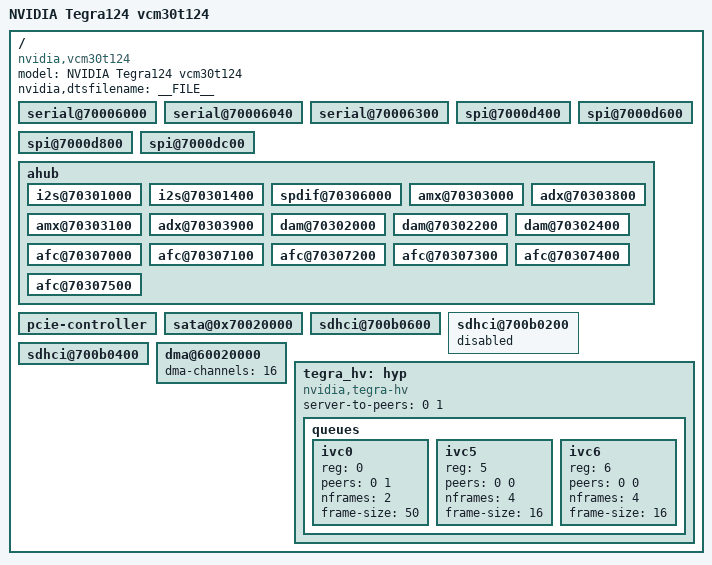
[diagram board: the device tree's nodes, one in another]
/*
 * arch/arm/boot/dts/tegra124-vcm30_t124.dts
 *
 * Copyright (c) 2013-2014, NVIDIA CORPORATION.  All rights reserved.
 *
 * This program is free software; you can redistribute it and/or modify
 * it under the terms of the GNU General Public License as published by
 * the Free Software Foundation; version 2 of the License.
 *
 * This program is distributed in the hope that it will be useful, but WITHOUT
 * ANY WARRANTY; without even the implied warranty of MERCHANTABILITY or
 * FITNESS FOR A PARTICULAR PURPOSE.  See the GNU General Public License for
 * more details.
 *
 * You should have received a copy of the GNU General Public License along
 * with this program; if not, write to the Free Software Foundation, Inc.,
 * 51 Franklin Street, Fifth Floor, Boston, MA  02110-1301, USA.
 *
 */

 /dts-v1/;

#include "tegra124-vcm30_t124.dtsi"
#include <tegra124-platforms/tegra124-vcm30-t124-gpio-default.dtsi>
#include <tegra124-platforms/tegra124-vcm30-t124-pinmux.dtsi>


/ {
	model = "NVIDIA Tegra124 vcm30t124";
	compatible = "nvidia,vcm30t124", "nvidia,tegra124";
	nvidia,dtsfilename = __FILE__;
	#address-cells = <2>;
	#size-cells = <2>;

        serial@70006000 {
                status = "okay";
        };

        serial@70006040 {
                status = "okay";
        };

        serial@70006300 {
                status = "okay";
        };

	spi@7000d400 {
		status = "okay";
	};

	spi@7000d600 {
		status = "okay";
	};

	spi@7000d800 {
		status = "okay";
	};

	spi@7000dc00 {
		status = "okay";
	};

	ahub {
		status = "okay";

		i2s@70301000 {
			status = "okay";
		};
		i2s@70301400 {
			status = "okay";
		};
		spdif@70306000 {
			status = "okay";
		};
		amx@70303000 {
			status = "okay";
		};
		adx@70303800 {
			status = "okay";
		};
		amx@70303100 {
			status = "okay";
		};
		adx@70303900 {
			status = "okay";
		};
		dam@70302000 {
			status = "okay";
		};
		dam@70302200 {
			status = "okay";
		};
		dam@70302400 {
			status = "okay";
		};
		afc@70307000 {
			status = "okay";
		};
		afc@70307100 {
			status = "okay";
		};
		afc@70307200 {
			status = "okay";
		};
		afc@70307300 {
			status = "okay";
		};
		afc@70307400 {
			status = "okay";
		};
		afc@70307500 {
			status = "okay";
		};
	};

	pcie-controller {
		status = "okay";
	};

	sata@0x70020000 {
		status = "okay";
	};

	sdhci@700b0600 {
		status = "okay";
	};

	sdhci@700b0200 {
		status = "disabled";
	};

	sdhci@700b0400 {
		status = "okay";
	};

	dma@60020000 {
		dma-channels = <16>;
		status = "okay";
	};

	tegra_hv: hyp {
		compatible = "nvidia,tegra-hv";
		status = "okay";

		server-to-peers = <0 1>;

		queues {
			#address-cells = <1>;
			#size-cells = <0>;

			/* guest 0 <-> guest 1 (frame based) */
			ivc0 {
				reg = <0>;
				peers = <0 1>;
				nframes = <2>;
				frame-size = <50>;
			};

			/* placeholder for serial & net IVC channels */

			/* guest 0 <-> guest 0 (loop) */
			ivc5 {
				reg = <5>;
				peers = <0 0>;
				nframes = <4>;
				frame-size = <16>;
			};

			/* guest 0 <-> guest 0 (loop) */
			ivc6 {
				reg = <6>;
				peers = <0 0>;
				nframes = <4>;
				frame-size = <16>;
			};

		};
	};
};
